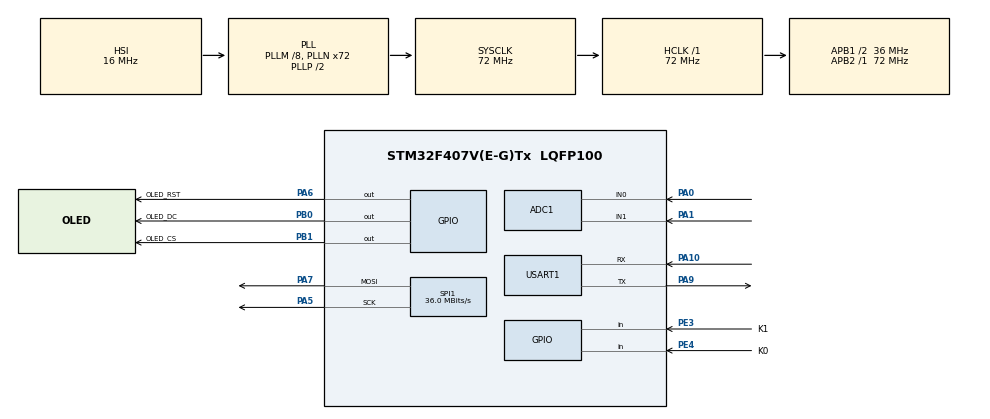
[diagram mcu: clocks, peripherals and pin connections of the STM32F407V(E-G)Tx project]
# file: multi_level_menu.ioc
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ADC1.Channel-0\#ChannelRegularConversion=ADC_CHANNEL_0
ADC1.Channel-1\#ChannelRegularConversion=ADC_CHANNEL_1
ADC1.ContinuousConvMode=ENABLE
ADC1.DMAContinuousRequests=ENABLE
ADC1.NbrOfConversion=2
ADC1.NbrOfConversionFlag=1
ADC1.Rank-0\#ChannelRegularConversion=1
ADC1.Rank-1\#ChannelRegularConversion=2
ADC1.SamplingTime-0\#ChannelRegularConversion=ADC_SAMPLETIME_3CYCLES
ADC1.SamplingTime-1\#ChannelRegularConversion=ADC_SAMPLETIME_3CYCLES
ADC1.ScanConvMode=ENABLE
ADC1.master=1
Dma.ADC1.1.Direction=DMA_PERIPH_TO_MEMORY
Dma.ADC1.1.FIFOMode=DMA_FIFOMODE_DISABLE
Dma.ADC1.1.Instance=DMA2_Stream0
Dma.ADC1.1.MemDataAlignment=DMA_MDATAALIGN_WORD
Dma.ADC1.1.MemInc=DMA_MINC_ENABLE
Dma.ADC1.1.Mode=DMA_CIRCULAR
Dma.ADC1.1.PeriphDataAlignment=DMA_PDATAALIGN_WORD
Dma.ADC1.1.PeriphInc=DMA_PINC_DISABLE
Dma.ADC1.1.Priority=DMA_PRIORITY_LOW
Dma.Request0=SPI1_TX
Dma.Request1=ADC1
Dma.SPI1_TX.0.Direction=DMA_MEMORY_TO_PERIPH
Dma.SPI1_TX.0.FIFOMode=DMA_FIFOMODE_DISABLE
Dma.SPI1_TX.0.Instance=DMA2_Stream3
Dma.SPI1_TX.0.MemDataAlignment=DMA_MDATAALIGN_BYTE
Dma.SPI1_TX.0.MemInc=DMA_MINC_ENABLE
Dma.SPI1_TX.0.Mode=DMA_NORMAL
Dma.SPI1_TX.0.PeriphDataAlignment=DMA_PDATAALIGN_BYTE
Dma.SPI1_TX.0.PeriphInc=DMA_PINC_DISABLE
Dma.SPI1_TX.0.Priority=DMA_PRIORITY_LOW
Mcu.Family=STM32F4
Mcu.Name=STM32F407V(E-G)Tx
Mcu.Package=LQFP100
NVIC.DMA2_Stream3_IRQn=true\:0\:0\:false\:false\:true\:false\:true\:true
NVIC.PriorityGroup=NVIC_PRIORITYGROUP_4
NVIC.TIM2_IRQn=true\:0\:0\:false\:false\:true\:true\:true\:true
NVIC.USART1_IRQn=true\:0\:0\:false\:false\:true\:true\:true\:true
PA0-WKUP.Signal=ADCx_IN0
PA1.Signal=ADCx_IN1
PA10.Mode=Asynchronous
PA10.Signal=USART1_RX
PA5.Mode=TX_Only_Simplex_Unidirect_Master
PA5.Signal=SPI1_SCK
PA6.GPIO_Label=OLED_RST
PA6.GPIO_Speed=GPIO_SPEED_FREQ_VERY_HIGH
PA6.PinState=GPIO_PIN_SET
PA6.Signal=GPIO_Output
PA7.Mode=TX_Only_Simplex_Unidirect_Master
PA7.Signal=SPI1_MOSI
PA9.Mode=Asynchronous
PA9.Signal=USART1_TX
PB0.GPIO_Label=OLED_DC
PB0.Signal=GPIO_Output
PB1.GPIO_Label=OLED_CS
PB1.Signal=GPIO_Output
PE3.GPIO_Label=K1
PE3.GPIO_PuPd=GPIO_PULLUP
PE3.Signal=GPIO_Input
PE4.GPIO_Label=K0
PE4.GPIO_PuPd=GPIO_PULLUP
PE4.Signal=GPIO_Input
ProjectManager.HeapSize=0x200
ProjectManager.StackSize=0x400
ProjectManager.TargetToolchain=MDK-ARM V5.32
RCC.48MHZClocksFreq_Value=36000000
RCC.AHBFreq_Value=72000000
RCC.APB1CLKDivider=RCC_HCLK_DIV2
RCC.APB1Freq_Value=36000000
RCC.APB1TimFreq_Value=72000000
RCC.APB2Freq_Value=72000000
RCC.APB2TimFreq_Value=72000000
RCC.CortexFreq_Value=72000000
RCC.HCLKFreq_Value=72000000
RCC.HSE_VALUE=25000000
RCC.HSI_VALUE=16000000
RCC.LSE_VALUE=32768
RCC.PLLM=8
RCC.PLLN=72
RCC.SYSCLKFreq_VALUE=72000000
RCC.SYSCLKSource=RCC_SYSCLKSOURCE_PLLCLK
RCC.VCOOutputFreq_Value=144000000
SH.ADCx_IN0.0=ADC1_IN0,IN0
SH.ADCx_IN1.0=ADC1_IN1,IN1
SPI1.CalculateBaudRate=36.0 MBits/s
SPI1.Direction=SPI_DIRECTION_2LINES
SPI1.Mode=SPI_MODE_MASTER
SPI1.VirtualType=VM_MASTER
TIM2.AutoReloadPreload=TIM_AUTORELOAD_PRELOAD_ENABLE
TIM2.Period=100-1
TIM2.Prescaler=720-1
USART1.VirtualMode=VM_ASYNC
VP_TIM2_VS_ClockSourceINT.Mode=Internal
board=custom

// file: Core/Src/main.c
/* USER CODE BEGIN Header */
/**
  ******************************************************************************
  * @file           : main.c
  * @brief          : Main program body
  ******************************************************************************
  * @attention
  *
  * Copyright (c) 2022 STMicroelectronics.
  * All rights reserved.
  *
  * This software is licensed under terms that can be found in the LICENSE file
  * in the root directory of this software component.
  * If no LICENSE file comes with this software, it is provided AS-IS.
  *
  ******************************************************************************
  */
/* USER CODE END Header */
#include "main.h"
#include "adc.h"
#include "dma.h"
#include "spi.h"
#include "tim.h"
#include "usart.h"
#include "gpio.h"

/* USER CODE BEGIN Includes */

#include "menu.h"

/* USER CODE END Includes */

void SystemClock_Config(void);

/* USER CODE BEGIN 0 */

uint32_t adcbuf[2] = {0};

/* USER CODE END 0 */

int main(void)
{

  /* MCU Configuration--------------------------------------------------------*/

  /* Reset of all peripherals, Initializes the Flash interface and the Systick. */
  HAL_Init();

  /* Configure the system clock */
  SystemClock_Config();

  /* Initialize all configured peripherals */
  MX_GPIO_Init();
  MX_DMA_Init();
  MX_SPI1_Init();
  MX_TIM2_Init();
  MX_ADC1_Init();
  MX_USART1_UART_Init();
  /* USER CODE BEGIN 2 */
	__HAL_UART_ENABLE_IT(&huart1, UART_IT_RXNE);

	MenuInit();//菜单初始化

	HAL_TIM_Base_Start_IT(&htim2);
	HAL_ADC_Start_DMA(&hadc1, adcbuf, 2);
  /* USER CODE END 2 */

  /* Infinite loop */
  while (1)
  {

    /* USER CODE BEGIN 3 */
	  MenuRun();
  }
  /* USER CODE END 3 */
}

void SystemClock_Config(void)
{
  RCC_OscInitTypeDef RCC_OscInitStruct = {0};
  RCC_ClkInitTypeDef RCC_ClkInitStruct = {0};

  /** Configure the main internal regulator output voltage
  */
  __HAL_RCC_PWR_CLK_ENABLE();
  __HAL_PWR_VOLTAGESCALING_CONFIG(PWR_REGULATOR_VOLTAGE_SCALE1);

  /** Initializes the RCC Oscillators according to the specified parameters
  * in the RCC_OscInitTypeDef structure.
  */
  RCC_OscInitStruct.OscillatorType = RCC_OSCILLATORTYPE_HSI;
  RCC_OscInitStruct.HSIState = RCC_HSI_ON;
  RCC_OscInitStruct.HSICalibrationValue = RCC_HSICALIBRATION_DEFAULT;
  RCC_OscInitStruct.PLL.PLLState = RCC_PLL_ON;
  RCC_OscInitStruct.PLL.PLLSource = RCC_PLLSOURCE_HSI;
  RCC_OscInitStruct.PLL.PLLM = 8;
  RCC_OscInitStruct.PLL.PLLN = 72;
  RCC_OscInitStruct.PLL.PLLP = RCC_PLLP_DIV2;
  RCC_OscInitStruct.PLL.PLLQ = 4;
  if (HAL_RCC_OscConfig(&RCC_OscInitStruct) != HAL_OK)
  {
    Error_Handler();
  }

  /** Initializes the CPU, AHB and APB buses clocks
  */
  RCC_ClkInitStruct.ClockType = RCC_CLOCKTYPE_HCLK|RCC_CLOCKTYPE_SYSCLK
                              |RCC_CLOCKTYPE_PCLK1|RCC_CLOCKTYPE_PCLK2;
  RCC_ClkInitStruct.SYSCLKSource = RCC_SYSCLKSOURCE_PLLCLK;
  RCC_ClkInitStruct.AHBCLKDivider = RCC_SYSCLK_DIV1;
  RCC_ClkInitStruct.APB1CLKDivider = RCC_HCLK_DIV2;
  RCC_ClkInitStruct.APB2CLKDivider = RCC_HCLK_DIV1;

  if (HAL_RCC_ClockConfig(&RCC_ClkInitStruct, FLASH_LATENCY_2) != HAL_OK)
  {
    Error_Handler();
  }
}

void Error_Handler(void)
{
  __disable_irq();
  while (1)
  {
  }
}
